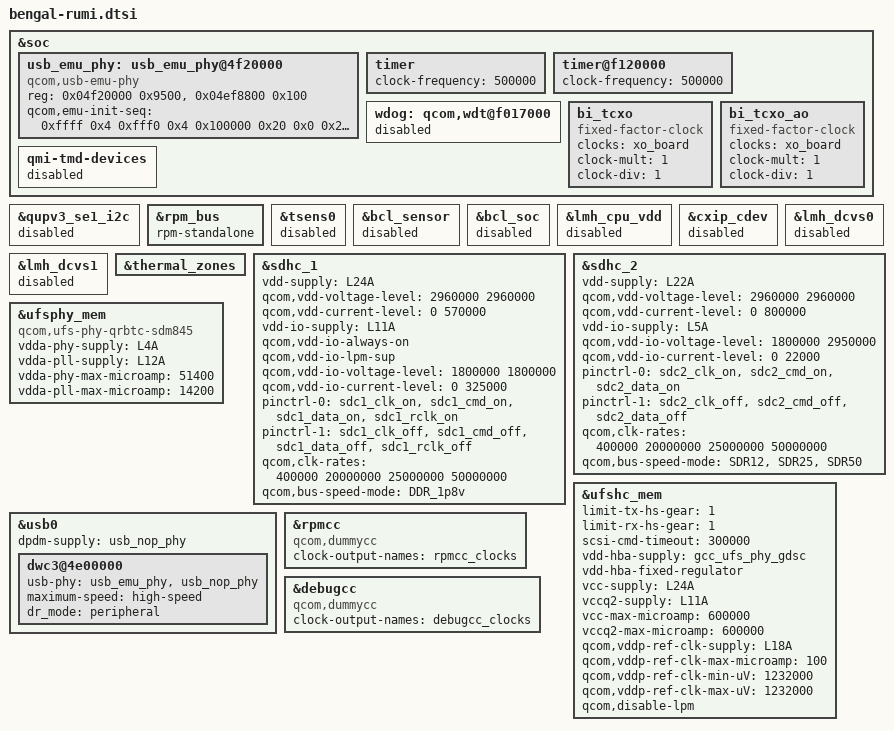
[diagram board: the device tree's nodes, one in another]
&soc {
	usb_emu_phy: usb_emu_phy@4f20000 {
			compatible = "qcom,usb-emu-phy";
			reg = <0x04f20000 0x9500>,
				<0x04ef8800 0x100>;
			reg-names = "base", "qscratch_base";


			qcom,emu-init-seq = <0xffff 0x4
					     0xfff0 0x4
					     0x100000 0x20
					     0x0 0x20
					     0x101f0 0x20
					     0x100000 0x3c
					     0x0 0x3c
					     0x10060 0x3c
					     0x0 0x4>;
	};

	timer {
		clock-frequency = <500000>;
	};

	timer@f120000 {
		clock-frequency = <500000>;
	};

	wdog: qcom,wdt@f017000 {
		status = "disabled";
	};

	bi_tcxo: bi_tcxo {
		compatible = "fixed-factor-clock";
		clocks = <&xo_board>;
		clock-mult = <1>;
		clock-div = <1>;
		#clock-cells = <0>;
	};

	bi_tcxo_ao: bi_tcxo_ao {
		compatible = "fixed-factor-clock";
		clocks = <&xo_board>;
		clock-mult = <1>;
		clock-div = <1>;
		#clock-cells = <0>;
	};

	qmi-tmd-devices {
		status = "disabled";
	};
};

&qupv3_se1_i2c {
	status = "disabled";
};

&rpm_bus {
	rpm-standalone;
	/delete-node/ rpm-regulator-smpa3;
	/delete-node/ rpm-regulator-smpa5;
	/delete-node/ rpm-regulator-smpa6;
	/delete-node/ rpm-regulator-smpa7;
	/delete-node/ rpm-regulator-smpa8;
	/delete-node/ rpm-regulator-ldoa1;
	/delete-node/ rpm-regulator-ldoa2;
	/delete-node/ rpm-regulator-ldoa3;
	/delete-node/ rpm-regulator-ldoa4;
	/delete-node/ rpm-regulator-ldoa5;
	/delete-node/ rpm-regulator-ldoa6;
	/delete-node/ rpm-regulator-ldoa7;
	/delete-node/ rpm-regulator-ldoa8;
	/delete-node/ rpm-regulator-ldoa9;
	/delete-node/ rpm-regulator-ldoa10;
	/delete-node/ rpm-regulator-ldoa11;
	/delete-node/ rpm-regulator-ldoa12;
	/delete-node/ rpm-regulator-ldoa13;
	/delete-node/ rpm-regulator-ldoa14;
	/delete-node/ rpm-regulator-ldoa15;
	/delete-node/ rpm-regulator-ldoa16;
	/delete-node/ rpm-regulator-ldoa17;
	/delete-node/ rpm-regulator-ldoa18;
	/delete-node/ rpm-regulator-ldoa19;
	/delete-node/ rpm-regulator-ldoa20;
	/delete-node/ rpm-regulator-ldoa21;
	/delete-node/ rpm-regulator-ldoa22;
	/delete-node/ rpm-regulator-ldoa23;
	/delete-node/ rpm-regulator-ldoa24;
};

&tsens0 {
	status = "disabled";
};

&bcl_sensor {
	status = "disabled";
};

&bcl_soc {
	status = "disabled";
};

&lmh_cpu_vdd {
	status = "disabled";
};

&cxip_cdev {
	status = "disabled";
};

&lmh_dcvs0 {
	status = "disabled";
};

&lmh_dcvs1 {
	status = "disabled";
};

&thermal_zones {
	/delete-node/ mapss-lowf;
	/delete-node/ camera-lowf;
	/delete-node/ pmi632-ibat-lvl0;
	/delete-node/ pmi632-ibat-lvl1;
	/delete-node/ pmi632-vbat-lvl0;
	/delete-node/ pmi632-vbat-lvl1;
	/delete-node/ pmi632-vbat-lvl2;
	/delete-node/ pmi632-bcl-lvl0;
	/delete-node/ pmi632-bcl-lvl1;
	/delete-node/ pmi632-bcl-lvl2;
};

 #include "bengal-stub-regulator.dtsi"

&sdhc_1 {
	vdd-supply = <&L24A>;
	qcom,vdd-voltage-level = <2960000 2960000>;
	qcom,vdd-current-level = <0 570000>;

	vdd-io-supply = <&L11A>;
	qcom,vdd-io-always-on;
	qcom,vdd-io-lpm-sup;
	qcom,vdd-io-voltage-level = <1800000 1800000>;
	qcom,vdd-io-current-level = <0 325000>;

	pinctrl-names = "active", "sleep";
	pinctrl-0 = <&sdc1_clk_on &sdc1_cmd_on &sdc1_data_on
					&sdc1_rclk_on>;
	pinctrl-1 = <&sdc1_clk_off &sdc1_cmd_off &sdc1_data_off
					&sdc1_rclk_off>;

	qcom,clk-rates = <400000 20000000 25000000 50000000>;
	qcom,bus-speed-mode = "DDR_1p8v";

	/delete-property/qcom,devfreq,freq-table;

	status = "ok";
};

&sdhc_2 {
	vdd-supply = <&L22A>;
	qcom,vdd-voltage-level = <2960000 2960000>;
	qcom,vdd-current-level = <0 800000>;

	vdd-io-supply = <&L5A>;
	qcom,vdd-io-voltage-level = <1800000 2950000>;
	qcom,vdd-io-current-level = <0 22000>;

	pinctrl-names = "active", "sleep";
	pinctrl-0 = <&sdc2_clk_on  &sdc2_cmd_on &sdc2_data_on>;
	pinctrl-1 = <&sdc2_clk_off &sdc2_cmd_off &sdc2_data_off>;

	qcom,clk-rates = <400000 20000000 25000000 50000000>;
	qcom,bus-speed-mode = "SDR12", "SDR25", "SDR50";

	/delete-property/qcom,devfreq,freq-table;

	status = "ok";
};

&ufsphy_mem {
	compatible = "qcom,ufs-phy-qrbtc-sdm845";

	vdda-phy-supply = <&L4A>; /* 0.9v */
	vdda-pll-supply = <&L12A>; /* 1.8v */
	vdda-phy-max-microamp = <51400>;
	vdda-pll-max-microamp = <14200>;

	status = "ok";
};

&ufshc_mem {
	limit-tx-hs-gear = <1>;
	limit-rx-hs-gear = <1>;
	scsi-cmd-timeout = <300000>;

	vdd-hba-supply = <&gcc_ufs_phy_gdsc>;
	vdd-hba-fixed-regulator;
	vcc-supply = <&L24A>;
	vccq2-supply = <&L11A>;
	vcc-max-microamp = <600000>;
	vccq2-max-microamp = <600000>;

	qcom,vddp-ref-clk-supply = <&L18A>;
	qcom,vddp-ref-clk-max-microamp = <100>;
	qcom,vddp-ref-clk-min-uV = <1232000>;
	qcom,vddp-ref-clk-max-uV = <1232000>;

	qcom,disable-lpm;
	status = "ok";
};

&usb0 {
	dpdm-supply = <&usb_nop_phy>;
	dwc3@4e00000 {
		usb-phy = <&usb_emu_phy>, <&usb_nop_phy>;
		maximum-speed = "high-speed";
		dr_mode = "peripheral";
	};
};

&rpmcc {
	compatible = "qcom,dummycc";
	clock-output-names = "rpmcc_clocks";
	#clock-cells = <1>;
	#reset-cells = <1>;
};

&debugcc {
	compatible = "qcom,dummycc";
	clock-output-names = "debugcc_clocks";
};
